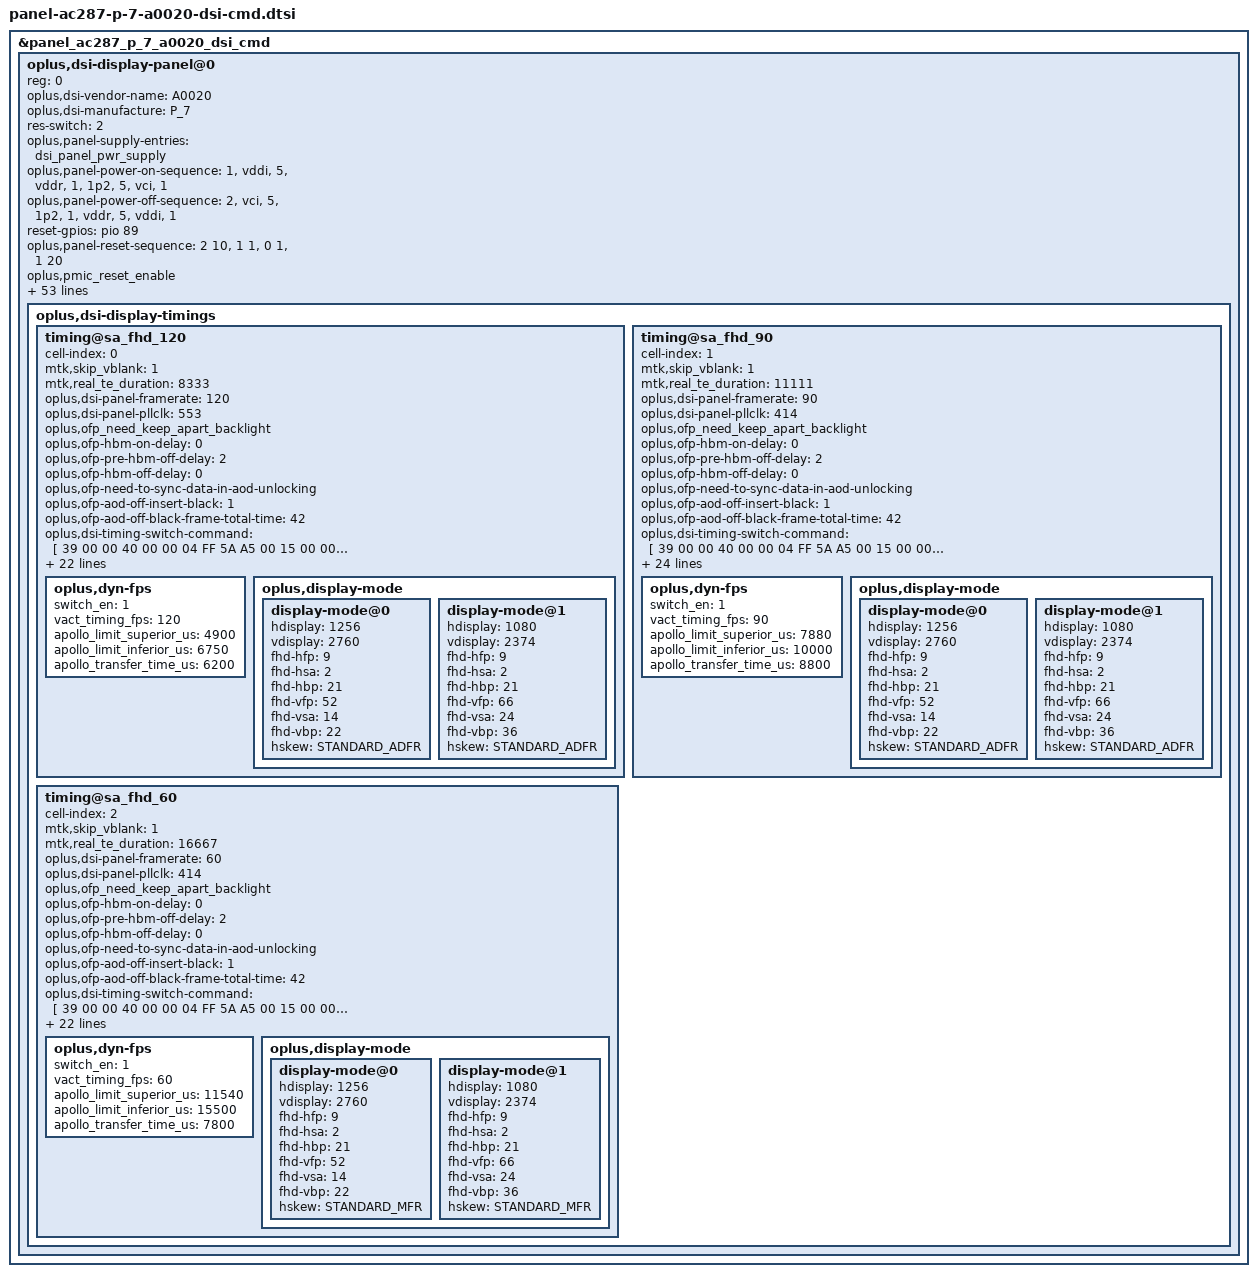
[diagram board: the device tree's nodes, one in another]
&panel_ac287_p_7_a0020_dsi_cmd {
	oplus,dsi-display-panel@0 {
		reg = <0>;
		oplus,dsi-vendor-name = "A0020";
		oplus,dsi-manufacture = "P_7";
		/* round corner */
		#include "panel-ac287-p-7-a0020-dsi-cmd-round-corner.dtsi"
		oplus,dsi-display-timings {
			timing@sa_fhd_120 {
				cell-index = <0>;
				mtk,skip_vblank = <1>;
				mtk,real_te_duration = <8333>;
				oplus,dsi-panel-framerate = <120>;
				oplus,dsi-panel-pllclk = <553>;
				/* OPLUS_FEATURE_DISPLAY_ONSCREENFINGERPRINT */
				oplus,ofp_need_keep_apart_backlight;
				oplus,ofp-hbm-on-delay = <0>;
				oplus,ofp-pre-hbm-off-delay = <2>;
				oplus,ofp-hbm-off-delay = <0>;
				oplus,ofp-need-to-sync-data-in-aod-unlocking;
				oplus,ofp-aod-off-insert-black = <1>;
				oplus,ofp-aod-off-black-frame-total-time = <42>;
				#include "panel-ac287-p-7-a0020-dsi-cmd-common.dtsi"
				oplus,dsi-timing-switch-command = [
					39 00 00 40 00 00 04 FF 5A A5 00
					15 00 00 40 00 00 02 60 00
					15 00 00 00 00 00 02 7D 00
				];
				oplus,dsi-on-command = [
					39 00 00 40 00 00 04 FF 5A A5 08 // 1~2: Sleepoutdon'treload
					15 00 00 40 00 00 02 C8 62
					39 00 00 40 00 00 04 FF 5A A5 21 // 3~4:  Flashreloadenable
					15 00 00 40 00 00 02 A4 38
					39 00 00 40 00 00 04 FF 5A A5 23
					15 00 00 40 00 00 02 85 15
					39 00 00 40 00 00 04 FF 5A A5 07
					15 00 00 40 00 00 02 8A 01
					39 00 00 40 00 00 03 8B 21 E0
					39 00 00 40 00 00 64 80 00 00 00 00 00 12 00 00 AB 30 80 0A C8 04 E8 00 14 02 74 02 74 02 00 02 56 00 20 01 B9 00 08 00 0D 05 7A 04 64 18 00 11 00 07 10 20 00 06 0F 0F 33 0E 1C 2A 38 46 54 62 69 70 77 79 7B 7D 7E 02 02 22 00 2A 40 2A BE 3A FC 3A FA 3A F8 3B 38 3B 78 3B B6 4B B6 4B F4 4B F4 6C 34 84 74 00 00 00 00 00 00
					39 00 00 40 00 00 64 81 00 00 00 00 00 12 00 00 A0 21 00 0A C8 04 E8 00 14 02 74 02 74 01 55 01 D6 00 0A 01 10 00 34 00 0D 05 7A 18 C0 08 00 0C 10 07 10 20 00 06 0F 0F 33 0E 1C 2A 38 46 54 62 69 70 77 79 7B 7D 7E 00 82 11 40 19 C0 22 3E 32 7C 3A BA 3A F8 3B 38 3B 38 3B 76 4B 76 4B 74 4B 74 5B B4 73 F4 01 00 00 00 00 00
					39 00 00 40 00 00 04 FF 5A A5 07
					15 00 00 40 00 00 02 91 00
					39 00 00 40 00 00 04 FF 5A A5 14
					15 00 00 40 00 00 02 82 01       //SPR IN AP ON
					39 00 00 40 00 00 04 FF 5A A5 14
					15 00 00 40 00 00 02 80 00      //DDIC SPR OFF
					// DDIC corner off
					39 00 00 40 00 00 04 FF 5A A5 17
					15 00 00 40 00 00 02 A0 0C
					39 00 00 40 00 00 04 FF 5A A5 13
					15 00 00 40 00 00 02 F9 30
					// 1 bit esd
					39 00 00 40 00 00 04 FF 5A A5 06
					15 00 00 40 00 00 02 C6 01
					39 00 00 40 00 00 04 FF 5A A5 08
					15 00 00 40 00 00 02 D2 05
					15 00 00 40 00 00 02 D3 01
					39 00 00 40 00 00 09 ED FF FF FF FF FF FF 45 FF
					39 00 00 40 00 00 09 EE FF FD FF FD F9 FA BE 76
					39 00 00 40 00 00 04 FF 5A A5 24
					39 00 00 40 00 00 31 D2 10 ED 04 83 03 0B 02 30 01 7A 00 FC 00 A9 00 01 00 00 00 00 00 00 00 00 00 00 00 00 00 00 00 00 00 00 00 00 00 00 00 00 00 00 00 00 00 00 00 00
					39 00 00 40 00 00 31 D3 04 84 03 0B 02 30 01 7A 00 FC 00 A9 00 01 00 00 00 00 00 00 00 00 00 00 00 00 00 00 00 00 00 00 00 00 00 00 00 00 00 00 00 00 00 00 00 00 00 00
					39 00 00 40 00 00 04 FF 5A A5 00
					15 00 00 40 00 00 02 5E 01
					15 00 00 40 00 00 02 60 00
					15 00 00 40 00 00 02 61 02
					15 00 00 40 00 00 02 6D 01
					15 00 00 40 00 00 02 35 00 //TE on
					15 00 00 40 00 00 02 53 20 // BC On
					// pull dowm pmic
					39 00 00 40 00 00 04 FF 5A A5 1C
					39 00 00 40 00 00 16 E1 10 80 9A 65 59 54 69 95 56 6A 55 99 9A 55 55 25 58 55 66 A2 00
					39 00 00 40 00 00 04 FF 5A A5 05
					15 00 00 40 00 00 02 83 01
					// LGOCB change to 30
					39 00 00 40 00 00 04 FF 5A A5 53
					39 00 00 40 00 00 1F A2 10 10 10 10 10 10 10 10 30 30 10 10 10 10 10 10 10 10 30 30 10 10 10 10 10 10 10 10 30 30
					39 00 00 00 00 00 04 FF 5A A5 00
					// crc reset
					39 00 00 40 00 00 04 FF 5A A5 08
					15 00 00 40 00 00 02 E0 22
					// timing switch
					39 00 00 40 00 00 04 FF 5A A5 22
					39 00 00 40 00 00 08 D8 00 FE 11 10 3A 18 18
					39 00 00 40 00 00 08 D9 01 03 11 10 50 18 18
					39 00 00 40 00 00 08 DA 01 04 11 10 50 19 19
					39 00 00 40 00 00 0A DC 84 94 BB 00 20 C4 A1 CC 10
					15 00 00 40 00 00 02 DD 01
					15 00 00 40 00 00 02 DE F1
					15 00 00 40 00 00 02 DF 80
					39 00 00 40 00 00 07 E0 02 00 5F 21 00 28
					39 00 00 40 00 00 04 FF 5A A5 00
					15 00 00 40 00 00 02 60 00
					15 00 00 00 00 00 02 7D 00
					// odc refresh
					39 00 00 40 00 00 04 FF 5A A5 49
					39 00 00 40 00 00 0C 80 00 08 0C 1C 3C 7C 8C CC 0C 00 01
					39 00 00 40 00 00 11 81 01 00 BD 00 18 01 85 01 42 02 A6 03 DD 06 FF 07
					39 00 00 40 00 00 13 82 01 00 BD 00 18 01 85 01 42 02 A6 03 DD 06 FF 07 00 00
					15 00 00 40 00 00 02 83 07
					15 00 00 40 00 00 02 84 0A
					39 00 00 40 00 00 04 85 08 0C 00
					39 00 00 40 00 00 04 86 40 80 00
					39 00 00 40 00 00 04 A0 40 40 40
					39 00 00 40 00 00 04 A1 40 40 40
					39 00 00 40 00 00 04 A2 40 40 40
					15 00 00 40 00 00 02 A6 3F
					15 00 00 40 00 00 02 A7 07
					15 00 00 40 00 00 02 AD 01
					15 00 00 40 00 00 02 AE 00
					15 00 00 40 00 00 02 AF 00
					15 00 00 40 00 00 02 D9 02
					15 00 00 40 00 00 02 DA F7
					15 00 00 40 00 00 02 DB 9C
					15 00 00 40 00 00 02 DC 03
					15 00 00 40 00 00 02 DF 06
					15 00 00 40 00 00 02 E0 01
					39 00 00 40 00 00 04 FF 5A A5 5A
					39 00 00 40 00 00 04 80 0D 0E 0D
					39 00 00 40 00 00 04 81 11 12 11
					39 00 00 40 00 00 04 82 07 08 07
					39 00 00 40 00 00 04 83 19 1C 1A
					39 00 00 40 00 00 04 84 14 15 13
					39 00 00 40 00 00 04 85 07 0A 08
					39 00 00 40 00 00 04 86 20 34 1A
					39 00 00 40 00 00 04 87 18 36 15
					39 00 00 40 00 00 04 88 1E 34 E0
					39 00 00 40 00 00 04 89 15 38 E0
					39 00 00 40 00 00 04 8A 32 32 32
					39 00 00 40 00 00 04 8B 2D 2D 28
					39 00 00 40 00 00 04 8C 27 1D 26
					39 00 00 40 00 00 04 8D 18 18 1D
					39 00 00 40 00 00 04 8E 0D 08 0D
					39 00 00 40 00 00 04 8F 20 24 24
					39 00 00 40 00 00 04 90 0D 10 10
					39 00 00 40 00 00 04 91 0F 10 10
					39 00 00 40 00 00 04 92 12 13 10
					39 00 00 40 00 00 04 93 05 05 06
					39 00 00 40 00 00 04 94 03 03 03
					39 00 00 40 00 00 04 95 33 37 3B
					39 00 00 40 00 00 04 96 32 33 2D
					39 00 00 40 00 00 04 97 26 27 22
					39 00 00 40 00 00 04 98 1A 1C 18
					39 00 00 40 00 00 04 99 12 13 10
					39 00 00 40 00 00 04 9A 06 07 06
					39 00 00 40 00 00 04 9B 04 04 03
					39 00 00 40 00 00 04 9C 36 3A 38
					39 00 00 40 00 00 04 9D 36 38 2D
					39 00 00 40 00 00 04 9E 24 26 16
					39 00 00 40 00 00 04 9F 1E 20 1C
					39 00 00 40 00 00 04 A0 15 17 14
					39 00 00 40 00 00 04 A1 0A 0B 0B
					39 00 00 40 00 00 04 A2 08 08 09
					39 00 00 40 00 00 04 A3 04 04 04
					39 00 00 40 00 00 04 A4 0B 0C 0B
					39 00 00 40 00 00 04 A5 0D 0E 0D
					39 00 00 40 00 00 04 A6 06 08 06
					39 00 00 40 00 00 04 A7 11 13 11
					39 00 00 40 00 00 04 A8 0F 10 10
					39 00 00 40 00 00 04 A9 05 06 05
					39 00 00 40 00 00 04 AA 19 1C 1B
					39 00 00 40 00 00 04 AB 14 17 15
					39 00 00 40 00 00 04 AC 0B 0F 0A
					39 00 00 40 00 00 04 AD 06 08 06
					39 00 00 40 00 00 04 AE 1B 1E 1B
					39 00 00 40 00 00 04 AF 18 1B 17
					39 00 00 40 00 00 04 B0 10 12 10
					39 00 00 40 00 00 04 B1 0D 0E 0A
					39 00 00 40 00 00 04 B2 03 05 04
					39 00 00 40 00 00 04 B3 18 1C 1A
					39 00 00 40 00 00 04 B4 16 18 16
					39 00 00 40 00 00 04 B5 12 14 10
					39 00 00 40 00 00 04 B6 07 0A 09
					39 00 00 40 00 00 04 B7 05 08 07
					39 00 00 40 00 00 04 B8 02 03 02
					39 00 00 40 00 00 04 B9 20 24 20
					39 00 00 40 00 00 04 BA 1C 1F 1D
					39 00 00 40 00 00 04 BB 16 1A 15
					39 00 00 40 00 00 04 BC 12 16 15
					39 00 00 40 00 00 04 BD 0B 0D 10
					39 00 00 40 00 00 04 BE 06 08 08
					39 00 00 40 00 00 04 BF 04 06 05
					39 00 00 40 00 00 04 C0 24 26 32
					39 00 00 40 00 00 04 C1 1D 17 23
					39 00 00 40 00 00 04 C2 1B 16 22
					39 00 00 40 00 00 04 C3 1A 17 20
					39 00 00 40 00 00 04 C4 17 16 1C
					39 00 00 40 00 00 04 C5 10 0F 0E
					39 00 00 40 00 00 04 C6 0F 0E 0B
					39 00 00 40 00 00 04 C7 0C 0D 0B
					39 00 00 40 00 00 04 C8 05 07 04
					39 00 00 40 00 00 04 C9 09 0C 09
					39 00 00 40 00 00 04 CA 04 06 05
					39 00 00 40 00 00 04 CB 14 1D 12
					39 00 00 40 00 00 04 CC 10 16 0D
					39 00 00 40 00 00 04 CD 03 05 02
					39 00 00 40 00 00 04 CE 0F 12 10
					39 00 00 40 00 00 04 CF 0E 10 0E
					39 00 00 40 00 00 04 D0 07 0A 08
					39 00 00 40 00 00 04 D1 02 04 01
					39 00 00 40 00 00 04 D2 17 1A 19
					39 00 00 40 00 00 04 D3 14 16 13
					39 00 00 40 00 00 04 D4 09 0C 0A
					39 00 00 40 00 00 04 D5 04 06 08
					39 00 00 40 00 00 04 D6 03 04 05
					39 00 00 40 00 00 04 D7 1D 1F 1C
					39 00 00 40 00 00 04 D8 0C 12 0D
					39 00 00 40 00 00 04 D9 09 0D 0B
					39 00 00 40 00 00 04 DA 06 0A 0A
					39 00 00 40 00 00 04 DB 05 05 07
					39 00 00 40 00 00 04 DC 01 03 01
					39 00 00 40 00 00 04 DD 22 23 20
					39 00 00 40 00 00 04 DE 15 18 1A
					39 00 00 40 00 00 04 DF 13 15 16
					39 00 00 40 00 00 04 E0 0F 13 14
					39 00 00 40 00 00 04 E1 0D 0F 10
					39 00 00 40 00 00 04 E2 07 08 08
					39 00 00 40 00 00 04 E3 06 07 06
					39 00 00 40 00 00 04 E4 2F 2D 35
					39 00 00 40 00 00 04 E5 20 20 28
					39 00 00 40 00 00 04 E6 1E 24 29
					39 00 00 40 00 00 04 E7 1B 1A 23
					39 00 00 40 00 00 04 E8 1B 1F 1E
					39 00 00 40 00 00 04 E9 0E 13 11
					39 00 00 40 00 00 04 EA 0B 10 0F
					39 00 00 40 00 00 04 EB 09 0A 07
					39 00 00 40 00 00 04 FF 5A A5 5B
					39 00 00 40 00 00 04 80 05 07 04
					39 00 00 40 00 00 04 81 05 08 07
					39 00 00 40 00 00 04 82 04 04 05
					39 00 00 40 00 00 04 83 11 16 0F
					39 00 00 40 00 00 04 84 0F 11 0D
					39 00 00 40 00 00 04 85 03 05 02
					39 00 00 40 00 00 04 86 08 0B 07
					39 00 00 40 00 00 04 87 04 05 06
					39 00 00 40 00 00 04 88 03 04 03
					39 00 00 40 00 00 04 89 02 02 01
					39 00 00 40 00 00 04 8A 11 14 13
					39 00 00 40 00 00 04 8B 0B 0D 0E
					39 00 00 40 00 00 04 8C 06 07 09
					39 00 00 40 00 00 04 8D 05 06 08
					39 00 00 40 00 00 04 8E 04 04 05
					39 00 00 40 00 00 04 8F 1A 1F 1D
					39 00 00 40 00 00 04 90 14 16 15
					39 00 00 40 00 00 04 91 0E 11 0F
					39 00 00 40 00 00 04 92 07 0A 09
					39 00 00 40 00 00 04 93 06 05 07
					39 00 00 40 00 00 04 94 02 03 01
					39 00 00 40 00 00 04 95 2E 32 31
					39 00 00 40 00 00 04 96 28 2C 2A
					39 00 00 40 00 00 04 97 18 1D 19
					39 00 00 40 00 00 04 98 13 14 13
					39 00 00 40 00 00 04 99 0F 0E 0F
					39 00 00 40 00 00 04 9A 07 08 08
					39 00 00 40 00 00 04 9B 06 07 06
					39 00 00 40 00 00 04 9C 2D 2E 3F
					39 00 00 40 00 00 04 9D 21 20 29
					39 00 00 40 00 00 04 9E 21 20 29
					39 00 00 40 00 00 04 9F 21 20 25
					39 00 00 40 00 00 04 A0 1B 17 1C
					39 00 00 40 00 00 04 A1 10 0F 13
					39 00 00 40 00 00 04 A2 0E 0D 0F
					39 00 00 40 00 00 04 A3 08 08 05
					39 00 00 40 00 00 04 A4 05 08 04
					39 00 00 40 00 00 04 A5 05 07 04
					39 00 00 40 00 00 04 A6 04 05 04
					39 00 00 40 00 00 04 A7 05 07 05
					39 00 00 40 00 00 04 A8 04 06 03
					39 00 00 40 00 00 04 A9 02 03 02
					39 00 00 40 00 00 04 AA 0F 11 10
					39 00 00 40 00 00 04 AB 0A 0B 08
					39 00 00 40 00 00 04 AC 06 07 05
					39 00 00 40 00 00 04 AD 03 02 02
					39 00 00 40 00 00 04 AE 11 14 12
					39 00 00 40 00 00 04 AF 0C 0F 0E
					39 00 00 40 00 00 04 B0 0B 0A 0A
					39 00 00 40 00 00 04 B1 05 07 08
					39 00 00 40 00 00 04 B2 04 04 05
					39 00 00 40 00 00 04 B3 16 15 14
					39 00 00 40 00 00 04 B4 0F 10 10
					39 00 00 40 00 00 04 B5 0D 0C 0B
					39 00 00 40 00 00 04 B6 09 08 07
					39 00 00 40 00 00 04 B7 05 05 06
					39 00 00 40 00 00 04 B8 01 01 01
					39 00 00 40 00 00 04 B9 1D 1C 21
					39 00 00 40 00 00 04 BA 16 16 1C
					39 00 00 40 00 00 04 BB 14 14 19
					39 00 00 40 00 00 04 BC 12 13 15
					39 00 00 40 00 00 04 BD 0D 0D 10
					39 00 00 40 00 00 04 BE 06 07 08
					39 00 00 40 00 00 04 BF 05 06 06
					39 00 00 40 00 00 04 C0 27 2E 3E
					39 00 00 40 00 00 04 C1 22 1C 2D
					39 00 00 40 00 00 04 C2 1E 20 26
					39 00 00 40 00 00 04 C3 1E 24 25
					39 00 00 40 00 00 04 C4 17 14 1A
					39 00 00 40 00 00 04 C5 0E 0F 0E
					39 00 00 40 00 00 04 C6 0C 0C 0D
					39 00 00 40 00 00 04 C7 04 05 05
					39 00 00 40 00 00 04 C8 05 07 04
					39 00 00 40 00 00 04 C9 04 06 04
					39 00 00 40 00 00 04 CA 03 04 03
					39 00 00 40 00 00 04 CB 07 07 08
					39 00 00 40 00 00 04 CC 02 03 03
					39 00 00 40 00 00 04 CD 00 01 01
					39 00 00 40 00 00 04 CE 06 06 08
					39 00 00 40 00 00 04 CF 03 04 03
					39 00 00 40 00 00 04 D0 02 03 02
					39 00 00 40 00 00 04 D1 01 03 01
					39 00 00 40 00 00 04 D2 11 11 14
					39 00 00 40 00 00 04 D3 0B 0C 0C
					39 00 00 40 00 00 04 D4 09 0A 0B
					39 00 00 40 00 00 04 D5 07 08 09
					39 00 00 40 00 00 04 D6 05 04 05
					39 00 00 40 00 00 04 D7 15 16 18
					39 00 00 40 00 00 04 D8 10 12 16
					39 00 00 40 00 00 04 D9 0D 0C 0F
					39 00 00 40 00 00 04 DA 09 0B 0B
					39 00 00 40 00 00 04 DB 07 06 07
					39 00 00 40 00 00 04 DC 01 01 01
					39 00 00 40 00 00 04 DD 23 1F 2C
					39 00 00 40 00 00 04 DE 1A 1C 1F
					39 00 00 40 00 00 04 DF 18 19 1B
					39 00 00 40 00 00 04 E0 13 16 16
					39 00 00 40 00 00 04 E1 0F 0F 10
					39 00 00 40 00 00 04 E2 07 08 07
					39 00 00 40 00 00 04 E3 05 06 06
					39 00 00 40 00 00 04 E4 37 36 3A
					39 00 00 40 00 00 04 E5 28 28 2D
					39 00 00 40 00 00 04 E6 27 27 2B
					39 00 00 40 00 00 04 E7 1D 22 23
					39 00 00 40 00 00 04 E8 1A 1A 19
					39 00 00 40 00 00 04 E9 10 0E 10
					39 00 00 40 00 00 04 EA 0E 0C 0D
					39 00 00 40 00 00 04 EB 05 05 05
					39 00 00 40 00 00 04 FF 5A A5 5C
					39 00 00 40 00 00 04 80 03 05 04
					39 00 00 40 00 00 04 81 03 03 03
					39 00 00 40 00 00 04 82 02 02 02
					39 00 00 40 00 00 04 83 04 05 04
					39 00 00 40 00 00 04 84 02 03 03
					39 00 00 40 00 00 04 85 01 02 02
					39 00 00 40 00 00 04 86 12 14 13
					39 00 00 40 00 00 04 87 0D 0E 0C
					39 00 00 40 00 00 04 88 0A 08 07
					39 00 00 40 00 00 04 89 04 04 03
					39 00 00 40 00 00 04 8A 1C 1C 1B
					39 00 00 40 00 00 04 8B 16 16 14
					39 00 00 40 00 00 04 8C 10 0F 0F
					39 00 00 40 00 00 04 8D 0A 0C 0A
					39 00 00 40 00 00 04 8E 05 07 06
					39 00 00 40 00 00 04 8F 20 21 22
					39 00 00 40 00 00 04 90 1C 1E 1D
					39 00 00 40 00 00 04 91 13 14 14
					39 00 00 40 00 00 04 92 0E 0F 0D
					39 00 00 40 00 00 04 93 05 07 06
					39 00 00 40 00 00 04 94 01 03 01
					39 00 00 40 00 00 04 95 2E 2E 33
					39 00 00 40 00 00 04 96 1D 1F 26
					39 00 00 40 00 00 04 97 17 1A 1C
					39 00 00 40 00 00 04 98 12 15 16
					39 00 00 40 00 00 04 99 0F 11 13
					39 00 00 40 00 00 04 9A 06 08 07
					39 00 00 40 00 00 04 9B 05 06 05
					39 00 00 40 00 00 04 9C 34 36 33
					39 00 00 40 00 00 04 9D 29 2C 29
					39 00 00 40 00 00 04 9E 29 2B 24
					39 00 00 40 00 00 04 9F 22 21 22
					39 00 00 40 00 00 04 A0 19 1F 18
					39 00 00 40 00 00 04 A1 0D 11 0C
					39 00 00 40 00 00 04 A2 0A 0D 0C
					39 00 00 40 00 00 04 A3 00 00 00
					39 00 00 40 00 00 04 A4 02 02 02
					39 00 00 40 00 00 04 A5 01 01 02
					39 00 00 40 00 00 04 A6 01 02 01
					39 00 00 40 00 00 04 A7 07 08 09
					39 00 00 40 00 00 04 A8 03 03 04
					39 00 00 40 00 00 04 A9 02 02 03
					39 00 00 40 00 00 04 AA 10 10 11
					39 00 00 40 00 00 04 AB 0E 0F 10
					39 00 00 40 00 00 04 AC 0A 0B 0C
					39 00 00 40 00 00 04 AD 04 04 04
					39 00 00 40 00 00 04 AE 18 19 1A
					39 00 00 40 00 00 04 AF 16 15 15
					39 00 00 40 00 00 04 B0 12 11 10
					39 00 00 40 00 00 04 B1 0C 0D 0D
					39 00 00 40 00 00 04 B2 05 05 05
					39 00 00 40 00 00 04 B3 21 20 22
					39 00 00 40 00 00 04 B4 18 17 16
					39 00 00 40 00 00 04 B5 0F 10 10
					39 00 00 40 00 00 04 B6 0C 0B 0D
					39 00 00 40 00 00 04 B7 07 06 07
					39 00 00 40 00 00 04 B8 01 01 01
					39 00 00 40 00 00 04 B9 32 30 36
					39 00 00 40 00 00 04 BA 1A 1B 1B
					39 00 00 40 00 00 04 BB 18 1A 18
					39 00 00 40 00 00 04 BC 13 14 13
					39 00 00 40 00 00 04 BD 0E 10 0C
					39 00 00 40 00 00 04 BE 06 08 05
					39 00 00 40 00 00 04 BF 05 05 04
					39 00 00 40 00 00 04 C0 30 2C 32
					39 00 00 40 00 00 04 C1 25 2A 26
					39 00 00 40 00 00 04 C2 1D 2C 22
					39 00 00 40 00 00 04 C3 1A 1E 1C
					39 00 00 40 00 00 04 C4 16 1C 12
					39 00 00 40 00 00 04 C5 0C 10 0A
					39 00 00 40 00 00 04 C6 0B 0C 08
					39 00 00 40 00 00 04 C7 00 00 00
					39 00 00 40 00 00 04 C8 05 06 03
					39 00 00 40 00 00 04 C9 03 05 02
					39 00 00 40 00 00 04 CA 03 05 02
					39 00 00 40 00 00 04 CB 03 05 02
					39 00 00 40 00 00 04 CC 02 03 02
					39 00 00 40 00 00 04 CD 00 00 00
					39 00 00 40 00 00 04 CE 00 00 00
					39 00 00 40 00 00 04 CF 00 00 00
					39 00 00 00 00 00 04 FF 5A A5 00
					39 00 00 00 78 00 01 11 // Sleep out
					39 00 00 00 00 00 01 29 // Display out
				];
				oplus,dsi-aod-off-command = [
					39 00 00 40 00 00 04 FF 5A A5 00
					39 00 00 40 00 00 02 38 00
					39 00 00 00 00 00 05 51 00 00 00 00
				];
				oplus,dsi-ultra-low-power-aod-on-command = [
				];
				oplus,dsi-ultra-low-power-aod-off-command = [
				];
				oplus,dsi-hbm-on-command = [
					39 00 00 00 00 00 03 51 0E 7A
				];
				oplus,dsi-hbm-off-command = [
					39 00 00 00 00 00 03 51 0D BB
				];

				oplus,dsi-timing-switch-command-state = "dsi_hs_mode";
				oplus,dsi-on-command-state = "dsi_lp_mode";
				oplus,dsi-aod-off-command-state = "dsi_ls_mode";
				oplus,dsi-ultra-low-power-aod-on-command-state = "dsi_ls_mode";
				oplus,dsi-ultra-low-power-aod-off-command-state = "dsi_ls_mode";
				oplus,dsi-hbm-on-command-state = "dsi_hs_mode";
				oplus,dsi-hbm-off-command-state = "dsi_hs_mode";
				oplus,dsc-params-entries = <&dsc_params>;
				oplus,spr-params-entries = <&spr_params>;
				oplus,dyn-fps {
					switch_en = <1>;
					vact_timing_fps = <120>;
					apollo_limit_superior_us = <4900>;
					apollo_limit_inferior_us = <6750>;
					apollo_transfer_time_us = <6200>;
				};
				oplus,display-mode {
					display-mode@0 {
						hdisplay = <1256>;
						vdisplay = <2760>;
						fhd-hfp = <9>;
						fhd-hsa = <2>;
						fhd-hbp = <21>;
						fhd-vfp = <52>;
						fhd-vsa = <14>;
						fhd-vbp = <22>;
						hskew = <STANDARD_ADFR>;
					};
					display-mode@1 {
						hdisplay = <1080>;
						vdisplay = <2374>;
						fhd-hfp = <9>;
						fhd-hsa = <2>;
						fhd-hbp = <21>;
						fhd-vfp = <66>;
						fhd-vsa = <24>;
						fhd-vbp = <36>;
						hskew = <STANDARD_ADFR>;
					};
				};
			};
			timing@sa_fhd_90 {
				cell-index = <1>;
				mtk,skip_vblank = <1>;
				mtk,real_te_duration = <11111>;
				oplus,dsi-panel-framerate = <90>;
				oplus,dsi-panel-pllclk = <414>;
				/* OPLUS_FEATURE_DISPLAY_ONSCREENFINGERPRINT */
				oplus,ofp_need_keep_apart_backlight;
				oplus,ofp-hbm-on-delay = <0>;
				oplus,ofp-pre-hbm-off-delay = <2>;
				oplus,ofp-hbm-off-delay = <0>;
				oplus,ofp-need-to-sync-data-in-aod-unlocking;
				oplus,ofp-aod-off-insert-black = <1>;
				oplus,ofp-aod-off-black-frame-total-time = <42>;
				#include "panel-ac287-p-7-a0020-dsi-cmd-common.dtsi"
				oplus,dsi-timing-switch-command = [
					39 00 00 40 00 00 04 FF 5A A5 00
					15 00 00 40 00 00 02 60 03
					15 00 00 00 00 00 02 7D 01
				];
				oplus,dsi-on-command = [
					39 00 00 40 00 00 04 FF 5A A5 08 // 1~2: Sleepoutdon'treload
					15 00 00 40 00 00 02 C8 62
					39 00 00 40 00 00 04 FF 5A A5 21 // 3~4:  Flashreloadenable
					15 00 00 40 00 00 02 A4 38
					39 00 00 40 00 00 04 FF 5A A5 23
					15 00 00 40 00 00 02 85 15
					39 00 00 40 00 00 04 FF 5A A5 07
					15 00 00 40 00 00 02 8A 01
					39 00 00 40 00 00 03 8B 21 E0
					39 00 00 40 00 00 64 80 00 00 00 00 00 12 00 00 AB 30 80 0A C8 04 E8 00 14 02 74 02 74 02 00 02 56 00 20 01 B9 00 08 00 0D 05 7A 04 64 18 00 11 00 07 10 20 00 06 0F 0F 33 0E 1C 2A 38 46 54 62 69 70 77 79 7B 7D 7E 02 02 22 00 2A 40 2A BE 3A FC 3A FA 3A F8 3B 38 3B 78 3B B6 4B B6 4B F4 4B F4 6C 34 84 74 00 00 00 00 00 00
					39 00 00 40 00 00 64 81 00 00 00 00 00 12 00 00 A0 21 00 0A C8 04 E8 00 14 02 74 02 74 01 55 01 D6 00 0A 01 10 00 34 00 0D 05 7A 18 C0 08 00 0C 10 07 10 20 00 06 0F 0F 33 0E 1C 2A 38 46 54 62 69 70 77 79 7B 7D 7E 00 82 11 40 19 C0 22 3E 32 7C 3A BA 3A F8 3B 38 3B 38 3B 76 4B 76 4B 74 4B 74 5B B4 73 F4 01 00 00 00 00 00
					39 00 00 40 00 00 04 FF 5A A5 07
					15 00 00 40 00 00 02 91 00
					39 00 00 40 00 00 04 FF 5A A5 14
					15 00 00 40 00 00 02 82 01       //SPR IN AP ON
					39 00 00 40 00 00 04 FF 5A A5 14
					15 00 00 40 00 00 02 80 00      //DDIC SPR OFF
					// DDIC corner off
					39 00 00 40 00 00 04 FF 5A A5 17
					15 00 00 40 00 00 02 A0 0C
					39 00 00 40 00 00 04 FF 5A A5 13
					15 00 00 40 00 00 02 F9 30
					// 1 bit esd
					39 00 00 40 00 00 04 FF 5A A5 06
					15 00 00 40 00 00 02 C6 01
					39 00 00 40 00 00 04 FF 5A A5 08
					15 00 00 40 00 00 02 D2 05
					15 00 00 40 00 00 02 D3 01
					39 00 00 40 00 00 09 ED FF FF FF FF FF FF 45 FF
					39 00 00 40 00 00 09 EE FF FD FF FD F9 FA BE 76
					39 00 00 40 00 00 04 FF 5A A5 24
					39 00 00 40 00 00 31 D2 10 ED 04 83 03 0B 02 30 01 7A 00 FC 00 A9 00 01 00 00 00 00 00 00 00 00 00 00 00 00 00 00 00 00 00 00 00 00 00 00 00 00 00 00 00 00 00 00 00 00
					39 00 00 40 00 00 31 D3 04 84 03 0B 02 30 01 7A 00 FC 00 A9 00 01 00 00 00 00 00 00 00 00 00 00 00 00 00 00 00 00 00 00 00 00 00 00 00 00 00 00 00 00 00 00 00 00 00 00
					39 00 00 40 00 00 04 FF 5A A5 00
					15 00 00 40 00 00 02 5E 01
					15 00 00 40 00 00 02 60 00
					15 00 00 40 00 00 02 61 02
					15 00 00 40 00 00 02 6D 01
					15 00 00 40 00 00 02 35 00 //TE on
					15 00 00 40 00 00 02 53 20 // BC On
					// pull dowm pmic
					39 00 00 40 00 00 04 FF 5A A5 1C
					39 00 00 40 00 00 16 E1 10 80 9A 65 59 54 69 95 56 6A 55 99 9A 55 55 25 58 55 66 A2 00
					39 00 00 40 00 00 04 FF 5A A5 05
					15 00 00 40 00 00 02 83 01
					// LGOCB change to 30
					39 00 00 40 00 00 04 FF 5A A5 53
					39 00 00 40 00 00 1F A2 10 10 10 10 10 10 10 10 30 30 10 10 10 10 10 10 10 10 30 30 10 10 10 10 10 10 10 10 30 30
					39 00 00 00 00 00 04 FF 5A A5 00
					// crc reset
					39 00 00 40 00 00 04 FF 5A A5 08
					15 00 00 40 00 00 02 E0 22
					// timing switch
					39 00 00 40 00 00 04 FF 5A A5 22
					39 00 00 40 00 00 08 D8 00 FE 11 10 3A 18 18
					39 00 00 40 00 00 08 D9 01 03 11 10 50 18 18
					39 00 00 40 00 00 08 DA 01 04 11 10 50 19 19
					39 00 00 40 00 00 0A DC 84 94 BB 00 20 C4 A1 CC 10
					15 00 00 40 00 00 02 DD 01
					15 00 00 40 00 00 02 DE F1
					15 00 00 40 00 00 02 DF 80
					39 00 00 40 00 00 07 E0 02 00 5F 21 00 28
					39 00 00 40 00 00 04 FF 5A A5 00
					15 00 00 40 00 00 02 60 03
					15 00 00 00 00 00 02 7D 01
					// odc refresh
					39 00 00 40 00 00 04 FF 5A A5 49
					39 00 00 40 00 00 0C 80 00 08 0C 1C 3C 7C 8C CC 0C 00 01
					39 00 00 40 00 00 11 81 01 00 BD 00 18 01 85 01 42 02 A6 03 DD 06 FF 07
					39 00 00 40 00 00 13 82 01 00 BD 00 18 01 85 01 42 02 A6 03 DD 06 FF 07 00 00
					15 00 00 40 00 00 02 83 07
					15 00 00 40 00 00 02 84 0A
					39 00 00 40 00 00 04 85 08 0C 00
					39 00 00 40 00 00 04 86 40 80 00
					39 00 00 40 00 00 04 A0 40 40 40
					39 00 00 40 00 00 04 A1 40 40 40
					39 00 00 40 00 00 04 A2 40 40 40
					15 00 00 40 00 00 02 A6 3F
					15 00 00 40 00 00 02 A7 07
					15 00 00 40 00 00 02 AD 01
					15 00 00 40 00 00 02 AE 00
					15 00 00 40 00 00 02 AF 00
					15 00 00 40 00 00 02 D9 02
					15 00 00 40 00 00 02 DA F7
					15 00 00 40 00 00 02 DB 9C
					15 00 00 40 00 00 02 DC 03
					15 00 00 40 00 00 02 DF 06
					15 00 00 40 00 00 02 E0 01
					39 00 00 40 00 00 04 FF 5A A5 5A
					39 00 00 40 00 00 04 80 0D 0E 0D
					39 00 00 40 00 00 04 81 11 12 11
					39 00 00 40 00 00 04 82 07 08 07
					39 00 00 40 00 00 04 83 19 1C 1A
					39 00 00 40 00 00 04 84 14 15 13
					39 00 00 40 00 00 04 85 07 0A 08
					39 00 00 40 00 00 04 86 20 34 1A
					39 00 00 40 00 00 04 87 18 36 15
					39 00 00 40 00 00 04 88 1E 34 E0
					39 00 00 40 00 00 04 89 15 38 E0
					39 00 00 40 00 00 04 8A 32 32 32
					39 00 00 40 00 00 04 8B 2D 2D 28
					39 00 00 40 00 00 04 8C 27 1D 26
					39 00 00 40 00 00 04 8D 18 18 1D
					39 00 00 40 00 00 04 8E 0D 08 0D
					39 00 00 40 00 00 04 8F 20 24 24
					39 00 00 40 00 00 04 90 0D 10 10
					39 00 00 40 00 00 04 91 0F 10 10
					39 00 00 40 00 00 04 92 12 13 10
					39 00 00 40 00 00 04 93 05 05 06
					39 00 00 40 00 00 04 94 03 03 03
					39 00 00 40 00 00 04 95 33 37 3B
					39 00 00 40 00 00 04 96 32 33 2D
					39 00 00 40 00 00 04 97 26 27 22
					39 00 00 40 00 00 04 98 1A 1C 18
					39 00 00 40 00 00 04 99 12 13 10
					39 00 00 40 00 00 04 9A 06 07 06
					39 00 00 40 00 00 04 9B 04 04 03
					39 00 00 40 00 00 04 9C 36 3A 38
					39 00 00 40 00 00 04 9D 36 38 2D
					39 00 00 40 00 00 04 9E 24 26 16
					39 00 00 40 00 00 04 9F 1E 20 1C
					39 00 00 40 00 00 04 A0 15 17 14
					39 00 00 40 00 00 04 A1 0A 0B 0B
					39 00 00 40 00 00 04 A2 08 08 09
					39 00 00 40 00 00 04 A3 04 04 04
					39 00 00 40 00 00 04 A4 0B 0C 0B
					39 00 00 40 00 00 04 A5 0D 0E 0D
					39 00 00 40 00 00 04 A6 06 08 06
					39 00 00 40 00 00 04 A7 11 13 11
					39 00 00 40 00 00 04 A8 0F 10 10
					39 00 00 40 00 00 04 A9 05 06 05
					39 00 00 40 00 00 04 AA 19 1C 1B
					39 00 00 40 00 00 04 AB 14 17 15
					39 00 00 40 00 00 04 AC 0B 0F 0A
					39 00 00 40 00 00 04 AD 06 08 06
					39 00 00 40 00 00 04 AE 1B 1E 1B
					39 00 00 40 00 00 04 AF 18 1B 17
					39 00 00 40 00 00 04 B0 10 12 10
					39 00 00 40 00 00 04 B1 0D 0E 0A
					39 00 00 40 00 00 04 B2 03 05 04
					39 00 00 40 00 00 04 B3 18 1C 1A
					39 00 00 40 00 00 04 B4 16 18 16
					39 00 00 40 00 00 04 B5 12 14 10
					39 00 00 40 00 00 04 B6 07 0A 09
					39 00 00 40 00 00 04 B7 05 08 07
					39 00 00 40 00 00 04 B8 02 03 02
					39 00 00 40 00 00 04 B9 20 24 20
					39 00 00 40 00 00 04 BA 1C 1F 1D
					39 00 00 40 00 00 04 BB 16 1A 15
					39 00 00 40 00 00 04 BC 12 16 15
					39 00 00 40 00 00 04 BD 0B 0D 10
					39 00 00 40 00 00 04 BE 06 08 08
					39 00 00 40 00 00 04 BF 04 06 05
					39 00 00 40 00 00 04 C0 24 26 32
					39 00 00 40 00 00 04 C1 1D 17 23
					39 00 00 40 00 00 04 C2 1B 16 22
					39 00 00 40 00 00 04 C3 1A 17 20
					39 00 00 40 00 00 04 C4 17 16 1C
					39 00 00 40 00 00 04 C5 10 0F 0E
					39 00 00 40 00 00 04 C6 0F 0E 0B
					39 00 00 40 00 00 04 C7 0C 0D 0B
					39 00 00 40 00 00 04 C8 05 07 04
					39 00 00 40 00 00 04 C9 09 0C 09
					39 00 00 40 00 00 04 CA 04 06 05
					39 00 00 40 00 00 04 CB 14 1D 12
					39 00 00 40 00 00 04 CC 10 16 0D
					39 00 00 40 00 00 04 CD 03 05 02
					39 00 00 40 00 00 04 CE 0F 12 10
					39 00 00 40 00 00 04 CF 0E 10 0E
					39 00 00 40 00 00 04 D0 07 0A 08
					39 00 00 40 00 00 04 D1 02 04 01
					39 00 00 40 00 00 04 D2 17 1A 19
					39 00 00 40 00 00 04 D3 14 16 13
					39 00 00 40 00 00 04 D4 09 0C 0A
					39 00 00 40 00 00 04 D5 04 06 08
					39 00 00 40 00 00 04 D6 03 04 05
					39 00 00 40 00 00 04 D7 1D 1F 1C
					39 00 00 40 00 00 04 D8 0C 12 0D
					39 00 00 40 00 00 04 D9 09 0D 0B
					39 00 00 40 00 00 04 DA 06 0A 0A
					39 00 00 40 00 00 04 DB 05 05 07
					39 00 00 40 00 00 04 DC 01 03 01
					39 00 00 40 00 00 04 DD 22 23 20
					39 00 00 40 00 00 04 DE 15 18 1A
					39 00 00 40 00 00 04 DF 13 15 16
					39 00 00 40 00 00 04 E0 0F 13 14
					39 00 00 40 00 00 04 E1 0D 0F 10
					39 00 00 40 00 00 04 E2 07 08 08
					39 00 00 40 00 00 04 E3 06 07 06
					39 00 00 40 00 00 04 E4 2F 2D 35
					39 00 00 40 00 00 04 E5 20 20 28
					39 00 00 40 00 00 04 E6 1E 24 29
					39 00 00 40 00 00 04 E7 1B 1A 23
					39 00 00 40 00 00 04 E8 1B 1F 1E
					39 00 00 40 00 00 04 E9 0E 13 11
					39 00 00 40 00 00 04 EA 0B 10 0F
					39 00 00 40 00 00 04 EB 09 0A 07
					39 00 00 40 00 00 04 FF 5A A5 5B
					39 00 00 40 00 00 04 80 05 07 04
					39 00 00 40 00 00 04 81 05 08 07
					39 00 00 40 00 00 04 82 04 04 05
					39 00 00 40 00 00 04 83 11 16 0F
					39 00 00 40 00 00 04 84 0F 11 0D
					39 00 00 40 00 00 04 85 03 05 02
					39 00 00 40 00 00 04 86 08 0B 07
					39 00 00 40 00 00 04 87 04 05 06
					39 00 00 40 00 00 04 88 03 04 03
					39 00 00 40 00 00 04 89 02 02 01
					39 00 00 40 00 00 04 8A 11 14 13
					39 00 00 40 00 00 04 8B 0B 0D 0E
					39 00 00 40 00 00 04 8C 06 07 09
					39 00 00 40 00 00 04 8D 05 06 08
					39 00 00 40 00 00 04 8E 04 04 05
					39 00 00 40 00 00 04 8F 1A 1F 1D
					39 00 00 40 00 00 04 90 14 16 15
					39 00 00 40 00 00 04 91 0E 11 0F
					39 00 00 40 00 00 04 92 07 0A 09
					39 00 00 40 00 00 04 93 06 05 07
					39 00 00 40 00 00 04 94 02 03 01
					39 00 00 40 00 00 04 95 2E 32 31
					39 00 00 40 00 00 04 96 28 2C 2A
					39 00 00 40 00 00 04 97 18 1D 19
					39 00 00 40 00 00 04 98 13 14 13
					39 00 00 40 00 00 04 99 0F 0E 0F
					39 00 00 40 00 00 04 9A 07 08 08
					39 00 00 40 00 00 04 9B 06 07 06
					39 00 00 40 00 00 04 9C 2D 2E 3F
					39 00 00 40 00 00 04 9D 21 20 29
					39 00 00 40 00 00 04 9E 21 20 29
					39 00 00 40 00 00 04 9F 21 20 25
					39 00 00 40 00 00 04 A0 1B 17 1C
					39 00 00 40 00 00 04 A1 10 0F 13
					39 00 00 40 00 00 04 A2 0E 0D 0F
					39 00 00 40 00 00 04 A3 08 08 05
					39 00 00 40 00 00 04 A4 05 08 04
					39 00 00 40 00 00 04 A5 05 07 04
					39 00 00 40 00 00 04 A6 04 05 04
					39 00 00 40 00 00 04 A7 05 07 05
					39 00 00 40 00 00 04 A8 04 06 03
					39 00 00 40 00 00 04 A9 02 03 02
					39 00 00 40 00 00 04 AA 0F 11 10
					39 00 00 40 00 00 04 AB 0A 0B 08
					39 00 00 40 00 00 04 AC 06 07 05
					39 00 00 40 00 00 04 AD 03 02 02
					39 00 00 40 00 00 04 AE 11 14 12
					39 00 00 40 00 00 04 AF 0C 0F 0E
					39 00 00 40 00 00 04 B0 0B 0A 0A
					39 00 00 40 00 00 04 B1 05 07 08
					39 00 00 40 00 00 04 B2 04 04 05
					39 00 00 40 00 00 04 B3 16 15 14
					39 00 00 40 00 00 04 B4 0F 10 10
					39 00 00 40 00 00 04 B5 0D 0C 0B
					39 00 00 40 00 00 04 B6 09 08 07
					39 00 00 40 00 00 04 B7 05 05 06
					39 00 00 40 00 00 04 B8 01 01 01
					39 00 00 40 00 00 04 B9 1D 1C 21
					39 00 00 40 00 00 04 BA 16 16 1C
					39 00 00 40 00 00 04 BB 14 14 19
					39 00 00 40 00 00 04 BC 12 13 15
					39 00 00 40 00 00 04 BD 0D 0D 10
					39 00 00 40 00 00 04 BE 06 07 08
					39 00 00 40 00 00 04 BF 05 06 06
					39 00 00 40 00 00 04 C0 27 2E 3E
					39 00 00 40 00 00 04 C1 22 1C 2D
					39 00 00 40 00 00 04 C2 1E 20 26
					39 00 00 40 00 00 04 C3 1E 24 25
					39 00 00 40 00 00 04 C4 17 14 1A
					39 00 00 40 00 00 04 C5 0E 0F 0E
					39 00 00 40 00 00 04 C6 0C 0C 0D
					39 00 00 40 00 00 04 C7 04 05 05
					39 00 00 40 00 00 04 C8 05 07 04
					39 00 00 40 00 00 04 C9 04 06 04
					39 00 00 40 00 00 04 CA 03 04 03
					39 00 00 40 00 00 04 CB 07 07 08
					39 00 00 40 00 00 04 CC 02 03 03
					39 00 00 40 00 00 04 CD 00 01 01
					39 00 00 40 00 00 04 CE 06 06 08
					39 00 00 40 00 00 04 CF 03 04 03
					39 00 00 40 00 00 04 D0 02 03 02
					39 00 00 40 00 00 04 D1 01 03 01
					39 00 00 40 00 00 04 D2 11 11 14
					39 00 00 40 00 00 04 D3 0B 0C 0C
					39 00 00 40 00 00 04 D4 09 0A 0B
					39 00 00 40 00 00 04 D5 07 08 09
					39 00 00 40 00 00 04 D6 05 04 05
					39 00 00 40 00 00 04 D7 15 16 18
					39 00 00 40 00 00 04 D8 10 12 16
					39 00 00 40 00 00 04 D9 0D 0C 0F
					39 00 00 40 00 00 04 DA 09 0B 0B
					39 00 00 40 00 00 04 DB 07 06 07
					39 00 00 40 00 00 04 DC 01 01 01
					39 00 00 40 00 00 04 DD 23 1F 2C
					39 00 00 40 00 00 04 DE 1A 1C 1F
					39 00 00 40 00 00 04 DF 18 19 1B
					39 00 00 40 00 00 04 E0 13 16 16
					39 00 00 40 00 00 04 E1 0F 0F 10
					39 00 00 40 00 00 04 E2 07 08 07
					39 00 00 40 00 00 04 E3 05 06 06
					39 00 00 40 00 00 04 E4 37 36 3A
					39 00 00 40 00 00 04 E5 28 28 2D
					39 00 00 40 00 00 04 E6 27 27 2B
					39 00 00 40 00 00 04 E7 1D 22 23
					39 00 00 40 00 00 04 E8 1A 1A 19
					39 00 00 40 00 00 04 E9 10 0E 10
					39 00 00 40 00 00 04 EA 0E 0C 0D
					39 00 00 40 00 00 04 EB 05 05 05
					39 00 00 40 00 00 04 FF 5A A5 5C
					39 00 00 40 00 00 04 80 03 05 04
					39 00 00 40 00 00 04 81 03 03 03
					39 00 00 40 00 00 04 82 02 02 02
					39 00 00 40 00 00 04 83 04 05 04
					39 00 00 40 00 00 04 84 02 03 03
					39 00 00 40 00 00 04 85 01 02 02
					39 00 00 40 00 00 04 86 12 14 13
					39 00 00 40 00 00 04 87 0D 0E 0C
					39 00 00 40 00 00 04 88 0A 08 07
					39 00 00 40 00 00 04 89 04 04 03
					39 00 00 40 00 00 04 8A 1C 1C 1B
					39 00 00 40 00 00 04 8B 16 16 14
					39 00 00 40 00 00 04 8C 10 0F 0F
					39 00 00 40 00 00 04 8D 0A 0C 0A
					39 00 00 40 00 00 04 8E 05 07 06
					39 00 00 40 00 00 04 8F 20 21 22
					39 00 00 40 00 00 04 90 1C 1E 1D
					39 00 00 40 00 00 04 91 13 14 14
					39 00 00 40 00 00 04 92 0E 0F 0D
					39 00 00 40 00 00 04 93 05 07 06
					39 00 00 40 00 00 04 94 01 03 01
					39 00 00 40 00 00 04 95 2E 2E 33
					39 00 00 40 00 00 04 96 1D 1F 26
					39 00 00 40 00 00 04 97 17 1A 1C
					39 00 00 40 00 00 04 98 12 15 16
					39 00 00 40 00 00 04 99 0F 11 13
					39 00 00 40 00 00 04 9A 06 08 07
					39 00 00 40 00 00 04 9B 05 06 05
					39 00 00 40 00 00 04 9C 34 36 33
					39 00 00 40 00 00 04 9D 29 2C 29
					39 00 00 40 00 00 04 9E 29 2B 24
					39 00 00 40 00 00 04 9F 22 21 22
					39 00 00 40 00 00 04 A0 19 1F 18
					39 00 00 40 00 00 04 A1 0D 11 0C
					39 00 00 40 00 00 04 A2 0A 0D 0C
					39 00 00 40 00 00 04 A3 00 00 00
					39 00 00 40 00 00 04 A4 02 02 02
					39 00 00 40 00 00 04 A5 01 01 02
					39 00 00 40 00 00 04 A6 01 02 01
					39 00 00 40 00 00 04 A7 07 08 09
					39 00 00 40 00 00 04 A8 03 03 04
					39 00 00 40 00 00 04 A9 02 02 03
					39 00 00 40 00 00 04 AA 10 10 11
					39 00 00 40 00 00 04 AB 0E 0F 10
					39 00 00 40 00 00 04 AC 0A 0B 0C
					39 00 00 40 00 00 04 AD 04 04 04
					39 00 00 40 00 00 04 AE 18 19 1A
					39 00 00 40 00 00 04 AF 16 15 15
					39 00 00 40 00 00 04 B0 12 11 10
					39 00 00 40 00 00 04 B1 0C 0D 0D
					39 00 00 40 00 00 04 B2 05 05 05
					39 00 00 40 00 00 04 B3 21 20 22
					39 00 00 40 00 00 04 B4 18 17 16
					39 00 00 40 00 00 04 B5 0F 10 10
					39 00 00 40 00 00 04 B6 0C 0B 0D
					39 00 00 40 00 00 04 B7 07 06 07
					39 00 00 40 00 00 04 B8 01 01 01
					39 00 00 40 00 00 04 B9 32 30 36
					39 00 00 40 00 00 04 BA 1A 1B 1B
					39 00 00 40 00 00 04 BB 18 1A 18
					39 00 00 40 00 00 04 BC 13 14 13
					39 00 00 40 00 00 04 BD 0E 10 0C
					39 00 00 40 00 00 04 BE 06 08 05
					39 00 00 40 00 00 04 BF 05 05 04
					39 00 00 40 00 00 04 C0 30 2C 32
					39 00 00 40 00 00 04 C1 25 2A 26
					39 00 00 40 00 00 04 C2 1D 2C 22
					39 00 00 40 00 00 04 C3 1A 1E 1C
					39 00 00 40 00 00 04 C4 16 1C 12
					39 00 00 40 00 00 04 C5 0C 10 0A
					39 00 00 40 00 00 04 C6 0B 0C 08
					39 00 00 40 00 00 04 C7 00 00 00
					39 00 00 40 00 00 04 C8 05 06 03
					39 00 00 40 00 00 04 C9 03 05 02
					39 00 00 40 00 00 04 CA 03 05 02
					39 00 00 40 00 00 04 CB 03 05 02
					39 00 00 40 00 00 04 CC 02 03 02
					39 00 00 40 00 00 04 CD 00 00 00
					39 00 00 40 00 00 04 CE 00 00 00
					39 00 00 40 00 00 04 CF 00 00 00
					39 00 00 00 00 00 04 FF 5A A5 00
					39 00 00 00 78 00 01 11 // Sleep out
					39 00 00 00 00 00 01 29 // Display out
				];
				oplus,dsi-aod-off-command = [
					39 00 00 40 00 00 04 FF 5A A5 00
					39 00 00 40 00 00 02 38 00
					39 00 00 00 00 00 05 51 00 00 00 00
				];
				oplus,dsi-ultra-low-power-aod-on-command = [
				];
				oplus,dsi-ultra-low-power-aod-off-command = [
				];
				oplus,dsi-hbm-on-command = [
					39 00 00 00 00 00 03 51 0E 7A
				];
				oplus,dsi-hbm-off-command = [
					39 00 00 00 00 00 03 51 0D BB
				];
				oplus,dsi-timing-switch-command-state = "dsi_hs_mode";
				oplus,dsi-timing-switch-1pulse-command-state = "dsi_hs_mode";
				oplus,dsi-on-command-state = "dsi_lp_mode";
				oplus,dsi-aod-off-command-state = "dsi_ls_mode";
				oplus,dsi-ultra-low-power-aod-on-command-state = "dsi_ls_mode";
				oplus,dsi-ultra-low-power-aod-off-command-state = "dsi_ls_mode";
				oplus,dsi-hbm-on-command-state = "dsi_hs_mode";
				oplus,dsi-hbm-off-command-state = "dsi_hs_mode";
				oplus,dsc-params-entries = <&dsc_params>;
				oplus,spr-params-entries = <&spr_params>;
				oplus,dyn-fps {
					switch_en = <1>;
					vact_timing_fps = <90>;
					apollo_limit_superior_us = <7880>;
					apollo_limit_inferior_us = <10000>;
					apollo_transfer_time_us = <8800>;
				};
				oplus,display-mode {
					display-mode@0 {
						hdisplay = <1256>;
						vdisplay = <2760>;
						fhd-hfp = <9>;
						fhd-hsa = <2>;
						fhd-hbp = <21>;
						fhd-vfp = <52>;
						fhd-vsa = <14>;
						fhd-vbp = <22>;
						hskew = <STANDARD_ADFR>;
					};
					display-mode@1 {
						hdisplay = <1080>;
						vdisplay = <2374>;
						fhd-hfp = <9>;
						fhd-hsa = <2>;
						fhd-hbp = <21>;
						fhd-vfp = <66>;
						fhd-vsa = <24>;
						fhd-vbp = <36>;
						hskew = <STANDARD_ADFR>;
					};
				};
			};
			timing@sa_fhd_60 {
				cell-index = <2>;
				mtk,skip_vblank = <1>;
				mtk,real_te_duration = <16667>;
				oplus,dsi-panel-framerate = <60>;
				oplus,dsi-panel-pllclk = <414>;
				/* OPLUS_FEATURE_DISPLAY_ONSCREENFINGERPRINT */
				oplus,ofp_need_keep_apart_backlight;
				oplus,ofp-hbm-on-delay = <0>;
				oplus,ofp-pre-hbm-off-delay = <2>;
				oplus,ofp-hbm-off-delay = <0>;
				oplus,ofp-need-to-sync-data-in-aod-unlocking;
				oplus,ofp-aod-off-insert-black = <1>;
				oplus,ofp-aod-off-black-frame-total-time = <42>;
				#include "panel-ac287-p-7-a0020-dsi-cmd-common.dtsi"
				oplus,dsi-timing-switch-command = [
					39 00 00 40 00 00 04 FF 5A A5 00
					15 00 00 40 00 00 02 60 04
					15 00 00 00 00 00 02 7D 01
				];
				oplus,dsi-on-command = [
					39 00 00 40 00 00 04 FF 5A A5 08 // 1~2: Sleepoutdon'treload
					15 00 00 40 00 00 02 C8 62
					39 00 00 40 00 00 04 FF 5A A5 21 // 3~4:  Flashreloadenable
					15 00 00 40 00 00 02 A4 38
					39 00 00 40 00 00 04 FF 5A A5 23
					15 00 00 40 00 00 02 85 15
					39 00 00 40 00 00 04 FF 5A A5 07
					15 00 00 40 00 00 02 8A 01
					39 00 00 40 00 00 03 8B 21 E0
					39 00 00 40 00 00 64 80 00 00 00 00 00 12 00 00 AB 30 80 0A C8 04 E8 00 14 02 74 02 74 02 00 02 56 00 20 01 B9 00 08 00 0D 05 7A 04 64 18 00 11 00 07 10 20 00 06 0F 0F 33 0E 1C 2A 38 46 54 62 69 70 77 79 7B 7D 7E 02 02 22 00 2A 40 2A BE 3A FC 3A FA 3A F8 3B 38 3B 78 3B B6 4B B6 4B F4 4B F4 6C 34 84 74 00 00 00 00 00 00
					39 00 00 40 00 00 64 81 00 00 00 00 00 12 00 00 A0 21 00 0A C8 04 E8 00 14 02 74 02 74 01 55 01 D6 00 0A 01 10 00 34 00 0D 05 7A 18 C0 08 00 0C 10 07 10 20 00 06 0F 0F 33 0E 1C 2A 38 46 54 62 69 70 77 79 7B 7D 7E 00 82 11 40 19 C0 22 3E 32 7C 3A BA 3A F8 3B 38 3B 38 3B 76 4B 76 4B 74 4B 74 5B B4 73 F4 01 00 00 00 00 00
					39 00 00 40 00 00 04 FF 5A A5 07
					15 00 00 40 00 00 02 91 00
					39 00 00 40 00 00 04 FF 5A A5 14
					15 00 00 40 00 00 02 82 01       //SPR IN AP ON
					39 00 00 40 00 00 04 FF 5A A5 14
					15 00 00 40 00 00 02 80 00      //DDIC SPR OFF
					// DDIC corner off
					39 00 00 40 00 00 04 FF 5A A5 17
					15 00 00 40 00 00 02 A0 0C
					39 00 00 40 00 00 04 FF 5A A5 13
					15 00 00 40 00 00 02 F9 30
					// 1 bit esd
					39 00 00 40 00 00 04 FF 5A A5 06
					15 00 00 40 00 00 02 C6 01
					39 00 00 40 00 00 04 FF 5A A5 08
					15 00 00 40 00 00 02 D2 05
					15 00 00 40 00 00 02 D3 01
					39 00 00 40 00 00 09 ED FF FF FF FF FF FF 45 FF
					39 00 00 40 00 00 09 EE FF FD FF FD F9 FA BE 76
					39 00 00 40 00 00 04 FF 5A A5 24
					39 00 00 40 00 00 31 D2 10 ED 04 83 03 0B 02 30 01 7A 00 FC 00 A9 00 01 00 00 00 00 00 00 00 00 00 00 00 00 00 00 00 00 00 00 00 00 00 00 00 00 00 00 00 00 00 00 00 00
					39 00 00 40 00 00 31 D3 04 84 03 0B 02 30 01 7A 00 FC 00 A9 00 01 00 00 00 00 00 00 00 00 00 00 00 00 00 00 00 00 00 00 00 00 00 00 00 00 00 00 00 00 00 00 00 00 00 00
					39 00 00 40 00 00 04 FF 5A A5 00
					15 00 00 40 00 00 02 5E 01
					15 00 00 40 00 00 02 60 00
					15 00 00 40 00 00 02 61 02
					15 00 00 40 00 00 02 6D 01
					15 00 00 40 00 00 02 35 00 //TE on
					15 00 00 40 00 00 02 53 20 // BC On
					// pull dowm pmic
					39 00 00 40 00 00 04 FF 5A A5 1C
					39 00 00 40 00 00 16 E1 10 80 9A 65 59 54 69 95 56 6A 55 99 9A 55 55 25 58 55 66 A2 00
					39 00 00 40 00 00 04 FF 5A A5 05
					15 00 00 40 00 00 02 83 01
					// LGOCB change to 30
					39 00 00 40 00 00 04 FF 5A A5 53
					39 00 00 40 00 00 1F A2 10 10 10 10 10 10 10 10 30 30 10 10 10 10 10 10 10 10 30 30 10 10 10 10 10 10 10 10 30 30
					39 00 00 00 00 00 04 FF 5A A5 00
					// crc reset
					39 00 00 40 00 00 04 FF 5A A5 08
					15 00 00 40 00 00 02 E0 22
					// timing switch
					39 00 00 40 00 00 04 FF 5A A5 22
					39 00 00 40 00 00 08 D8 00 FE 11 10 3A 18 18
					39 00 00 40 00 00 08 D9 01 03 11 10 50 18 18
					39 00 00 40 00 00 08 DA 01 04 11 10 50 19 19
					39 00 00 40 00 00 0A DC 84 94 BB 00 20 C4 A1 CC 10
					15 00 00 40 00 00 02 DD 01
					15 00 00 40 00 00 02 DE F1
					15 00 00 40 00 00 02 DF 80
					39 00 00 40 00 00 07 E0 02 00 5F 21 00 28
					39 00 00 40 00 00 04 FF 5A A5 00
					15 00 00 40 00 00 02 60 04
					15 00 00 00 00 00 02 7D 01
					// odc refresh
					39 00 00 40 00 00 04 FF 5A A5 49
					39 00 00 40 00 00 0C 80 00 08 0C 1C 3C 7C 8C CC 0C 00 01
					39 00 00 40 00 00 11 81 01 00 BD 00 18 01 85 01 42 02 A6 03 DD 06 FF 07
					39 00 00 40 00 00 13 82 01 00 BD 00 18 01 85 01 42 02 A6 03 DD 06 FF 07 00 00
					15 00 00 40 00 00 02 83 07
					15 00 00 40 00 00 02 84 0A
					39 00 00 40 00 00 04 85 08 0C 00
					39 00 00 40 00 00 04 86 40 80 00
					39 00 00 40 00 00 04 A0 40 40 40
					39 00 00 40 00 00 04 A1 40 40 40
					39 00 00 40 00 00 04 A2 40 40 40
					15 00 00 40 00 00 02 A6 3F
					15 00 00 40 00 00 02 A7 07
					15 00 00 40 00 00 02 AD 01
					15 00 00 40 00 00 02 AE 00
					15 00 00 40 00 00 02 AF 00
					15 00 00 40 00 00 02 D9 02
					15 00 00 40 00 00 02 DA F7
					15 00 00 40 00 00 02 DB 9C
					15 00 00 40 00 00 02 DC 03
					15 00 00 40 00 00 02 DF 06
					15 00 00 40 00 00 02 E0 01
					39 00 00 40 00 00 04 FF 5A A5 5A
					39 00 00 40 00 00 04 80 0D 0E 0D
					39 00 00 40 00 00 04 81 11 12 11
					39 00 00 40 00 00 04 82 07 08 07
					39 00 00 40 00 00 04 83 19 1C 1A
					39 00 00 40 00 00 04 84 14 15 13
					39 00 00 40 00 00 04 85 07 0A 08
					39 00 00 40 00 00 04 86 20 34 1A
					39 00 00 40 00 00 04 87 18 36 15
					39 00 00 40 00 00 04 88 1E 34 E0
					39 00 00 40 00 00 04 89 15 38 E0
					39 00 00 40 00 00 04 8A 32 32 32
					39 00 00 40 00 00 04 8B 2D 2D 28
					39 00 00 40 00 00 04 8C 27 1D 26
					39 00 00 40 00 00 04 8D 18 18 1D
					39 00 00 40 00 00 04 8E 0D 08 0D
					39 00 00 40 00 00 04 8F 20 24 24
					39 00 00 40 00 00 04 90 0D 10 10
					39 00 00 40 00 00 04 91 0F 10 10
					39 00 00 40 00 00 04 92 12 13 10
					39 00 00 40 00 00 04 93 05 05 06
					39 00 00 40 00 00 04 94 03 03 03
					39 00 00 40 00 00 04 95 33 37 3B
					39 00 00 40 00 00 04 96 32 33 2D
					39 00 00 40 00 00 04 97 26 27 22
					39 00 00 40 00 00 04 98 1A 1C 18
					39 00 00 40 00 00 04 99 12 13 10
					39 00 00 40 00 00 04 9A 06 07 06
					39 00 00 40 00 00 04 9B 04 04 03
					39 00 00 40 00 00 04 9C 36 3A 38
					39 00 00 40 00 00 04 9D 36 38 2D
					39 00 00 40 00 00 04 9E 24 26 16
					39 00 00 40 00 00 04 9F 1E 20 1C
					39 00 00 40 00 00 04 A0 15 17 14
					39 00 00 40 00 00 04 A1 0A 0B 0B
					39 00 00 40 00 00 04 A2 08 08 09
					39 00 00 40 00 00 04 A3 04 04 04
					39 00 00 40 00 00 04 A4 0B 0C 0B
					39 00 00 40 00 00 04 A5 0D 0E 0D
					39 00 00 40 00 00 04 A6 06 08 06
					39 00 00 40 00 00 04 A7 11 13 11
					39 00 00 40 00 00 04 A8 0F 10 10
					39 00 00 40 00 00 04 A9 05 06 05
					39 00 00 40 00 00 04 AA 19 1C 1B
					39 00 00 40 00 00 04 AB 14 17 15
					39 00 00 40 00 00 04 AC 0B 0F 0A
					39 00 00 40 00 00 04 AD 06 08 06
					39 00 00 40 00 00 04 AE 1B 1E 1B
					39 00 00 40 00 00 04 AF 18 1B 17
					39 00 00 40 00 00 04 B0 10 12 10
					39 00 00 40 00 00 04 B1 0D 0E 0A
					39 00 00 40 00 00 04 B2 03 05 04
					39 00 00 40 00 00 04 B3 18 1C 1A
					39 00 00 40 00 00 04 B4 16 18 16
					39 00 00 40 00 00 04 B5 12 14 10
					39 00 00 40 00 00 04 B6 07 0A 09
					39 00 00 40 00 00 04 B7 05 08 07
					39 00 00 40 00 00 04 B8 02 03 02
					39 00 00 40 00 00 04 B9 20 24 20
					39 00 00 40 00 00 04 BA 1C 1F 1D
					39 00 00 40 00 00 04 BB 16 1A 15
					39 00 00 40 00 00 04 BC 12 16 15
					39 00 00 40 00 00 04 BD 0B 0D 10
					39 00 00 40 00 00 04 BE 06 08 08
					39 00 00 40 00 00 04 BF 04 06 05
					39 00 00 40 00 00 04 C0 24 26 32
					39 00 00 40 00 00 04 C1 1D 17 23
					39 00 00 40 00 00 04 C2 1B 16 22
					39 00 00 40 00 00 04 C3 1A 17 20
					39 00 00 40 00 00 04 C4 17 16 1C
					39 00 00 40 00 00 04 C5 10 0F 0E
					39 00 00 40 00 00 04 C6 0F 0E 0B
					39 00 00 40 00 00 04 C7 0C 0D 0B
					39 00 00 40 00 00 04 C8 05 07 04
					39 00 00 40 00 00 04 C9 09 0C 09
					39 00 00 40 00 00 04 CA 04 06 05
					39 00 00 40 00 00 04 CB 14 1D 12
					39 00 00 40 00 00 04 CC 10 16 0D
					39 00 00 40 00 00 04 CD 03 05 02
					39 00 00 40 00 00 04 CE 0F 12 10
					39 00 00 40 00 00 04 CF 0E 10 0E
					39 00 00 40 00 00 04 D0 07 0A 08
					39 00 00 40 00 00 04 D1 02 04 01
					39 00 00 40 00 00 04 D2 17 1A 19
					39 00 00 40 00 00 04 D3 14 16 13
					39 00 00 40 00 00 04 D4 09 0C 0A
					39 00 00 40 00 00 04 D5 04 06 08
					39 00 00 40 00 00 04 D6 03 04 05
					39 00 00 40 00 00 04 D7 1D 1F 1C
					39 00 00 40 00 00 04 D8 0C 12 0D
					39 00 00 40 00 00 04 D9 09 0D 0B
					39 00 00 40 00 00 04 DA 06 0A 0A
					39 00 00 40 00 00 04 DB 05 05 07
					39 00 00 40 00 00 04 DC 01 03 01
					39 00 00 40 00 00 04 DD 22 23 20
					39 00 00 40 00 00 04 DE 15 18 1A
					39 00 00 40 00 00 04 DF 13 15 16
					39 00 00 40 00 00 04 E0 0F 13 14
					39 00 00 40 00 00 04 E1 0D 0F 10
					39 00 00 40 00 00 04 E2 07 08 08
					39 00 00 40 00 00 04 E3 06 07 06
					39 00 00 40 00 00 04 E4 2F 2D 35
					39 00 00 40 00 00 04 E5 20 20 28
					39 00 00 40 00 00 04 E6 1E 24 29
					39 00 00 40 00 00 04 E7 1B 1A 23
					39 00 00 40 00 00 04 E8 1B 1F 1E
					39 00 00 40 00 00 04 E9 0E 13 11
					39 00 00 40 00 00 04 EA 0B 10 0F
					39 00 00 40 00 00 04 EB 09 0A 07
					39 00 00 40 00 00 04 FF 5A A5 5B
					39 00 00 40 00 00 04 80 05 07 04
					39 00 00 40 00 00 04 81 05 08 07
					39 00 00 40 00 00 04 82 04 04 05
					39 00 00 40 00 00 04 83 11 16 0F
					39 00 00 40 00 00 04 84 0F 11 0D
					39 00 00 40 00 00 04 85 03 05 02
					39 00 00 40 00 00 04 86 08 0B 07
					39 00 00 40 00 00 04 87 04 05 06
					39 00 00 40 00 00 04 88 03 04 03
					39 00 00 40 00 00 04 89 02 02 01
					39 00 00 40 00 00 04 8A 11 14 13
					39 00 00 40 00 00 04 8B 0B 0D 0E
					39 00 00 40 00 00 04 8C 06 07 09
					39 00 00 40 00 00 04 8D 05 06 08
					39 00 00 40 00 00 04 8E 04 04 05
					39 00 00 40 00 00 04 8F 1A 1F 1D
					39 00 00 40 00 00 04 90 14 16 15
					39 00 00 40 00 00 04 91 0E 11 0F
					39 00 00 40 00 00 04 92 07 0A 09
					39 00 00 40 00 00 04 93 06 05 07
					39 00 00 40 00 00 04 94 02 03 01
					39 00 00 40 00 00 04 95 2E 32 31
					39 00 00 40 00 00 04 96 28 2C 2A
					39 00 00 40 00 00 04 97 18 1D 19
					39 00 00 40 00 00 04 98 13 14 13
					39 00 00 40 00 00 04 99 0F 0E 0F
					39 00 00 40 00 00 04 9A 07 08 08
					39 00 00 40 00 00 04 9B 06 07 06
					39 00 00 40 00 00 04 9C 2D 2E 3F
					39 00 00 40 00 00 04 9D 21 20 29
					39 00 00 40 00 00 04 9E 21 20 29
					39 00 00 40 00 00 04 9F 21 20 25
					39 00 00 40 00 00 04 A0 1B 17 1C
					39 00 00 40 00 00 04 A1 10 0F 13
					39 00 00 40 00 00 04 A2 0E 0D 0F
					39 00 00 40 00 00 04 A3 08 08 05
					39 00 00 40 00 00 04 A4 05 08 04
					39 00 00 40 00 00 04 A5 05 07 04
					39 00 00 40 00 00 04 A6 04 05 04
					39 00 00 40 00 00 04 A7 05 07 05
					39 00 00 40 00 00 04 A8 04 06 03
					39 00 00 40 00 00 04 A9 02 03 02
					39 00 00 40 00 00 04 AA 0F 11 10
					39 00 00 40 00 00 04 AB 0A 0B 08
					39 00 00 40 00 00 04 AC 06 07 05
					39 00 00 40 00 00 04 AD 03 02 02
					39 00 00 40 00 00 04 AE 11 14 12
					39 00 00 40 00 00 04 AF 0C 0F 0E
					39 00 00 40 00 00 04 B0 0B 0A 0A
					39 00 00 40 00 00 04 B1 05 07 08
					39 00 00 40 00 00 04 B2 04 04 05
					39 00 00 40 00 00 04 B3 16 15 14
					39 00 00 40 00 00 04 B4 0F 10 10
					39 00 00 40 00 00 04 B5 0D 0C 0B
					39 00 00 40 00 00 04 B6 09 08 07
					39 00 00 40 00 00 04 B7 05 05 06
					39 00 00 40 00 00 04 B8 01 01 01
					39 00 00 40 00 00 04 B9 1D 1C 21
					39 00 00 40 00 00 04 BA 16 16 1C
					39 00 00 40 00 00 04 BB 14 14 19
					39 00 00 40 00 00 04 BC 12 13 15
					39 00 00 40 00 00 04 BD 0D 0D 10
					39 00 00 40 00 00 04 BE 06 07 08
					39 00 00 40 00 00 04 BF 05 06 06
					39 00 00 40 00 00 04 C0 27 2E 3E
					39 00 00 40 00 00 04 C1 22 1C 2D
					39 00 00 40 00 00 04 C2 1E 20 26
					39 00 00 40 00 00 04 C3 1E 24 25
					39 00 00 40 00 00 04 C4 17 14 1A
					39 00 00 40 00 00 04 C5 0E 0F 0E
					39 00 00 40 00 00 04 C6 0C 0C 0D
					39 00 00 40 00 00 04 C7 04 05 05
					39 00 00 40 00 00 04 C8 05 07 04
					39 00 00 40 00 00 04 C9 04 06 04
					39 00 00 40 00 00 04 CA 03 04 03
					39 00 00 40 00 00 04 CB 07 07 08
					39 00 00 40 00 00 04 CC 02 03 03
					39 00 00 40 00 00 04 CD 00 01 01
					39 00 00 40 00 00 04 CE 06 06 08
					39 00 00 40 00 00 04 CF 03 04 03
					39 00 00 40 00 00 04 D0 02 03 02
					39 00 00 40 00 00 04 D1 01 03 01
					39 00 00 40 00 00 04 D2 11 11 14
					39 00 00 40 00 00 04 D3 0B 0C 0C
					39 00 00 40 00 00 04 D4 09 0A 0B
					39 00 00 40 00 00 04 D5 07 08 09
					39 00 00 40 00 00 04 D6 05 04 05
					39 00 00 40 00 00 04 D7 15 16 18
					39 00 00 40 00 00 04 D8 10 12 16
					39 00 00 40 00 00 04 D9 0D 0C 0F
					39 00 00 40 00 00 04 DA 09 0B 0B
					39 00 00 40 00 00 04 DB 07 06 07
					39 00 00 40 00 00 04 DC 01 01 01
					39 00 00 40 00 00 04 DD 23 1F 2C
					39 00 00 40 00 00 04 DE 1A 1C 1F
					39 00 00 40 00 00 04 DF 18 19 1B
					39 00 00 40 00 00 04 E0 13 16 16
					39 00 00 40 00 00 04 E1 0F 0F 10
					39 00 00 40 00 00 04 E2 07 08 07
					39 00 00 40 00 00 04 E3 05 06 06
					39 00 00 40 00 00 04 E4 37 36 3A
					39 00 00 40 00 00 04 E5 28 28 2D
					39 00 00 40 00 00 04 E6 27 27 2B
					39 00 00 40 00 00 04 E7 1D 22 23
					39 00 00 40 00 00 04 E8 1A 1A 19
					39 00 00 40 00 00 04 E9 10 0E 10
					39 00 00 40 00 00 04 EA 0E 0C 0D
					39 00 00 40 00 00 04 EB 05 05 05
					39 00 00 40 00 00 04 FF 5A A5 5C
					39 00 00 40 00 00 04 80 03 05 04
					39 00 00 40 00 00 04 81 03 03 03
					39 00 00 40 00 00 04 82 02 02 02
					39 00 00 40 00 00 04 83 04 05 04
					39 00 00 40 00 00 04 84 02 03 03
					39 00 00 40 00 00 04 85 01 02 02
					39 00 00 40 00 00 04 86 12 14 13
					39 00 00 40 00 00 04 87 0D 0E 0C
					39 00 00 40 00 00 04 88 0A 08 07
					39 00 00 40 00 00 04 89 04 04 03
					39 00 00 40 00 00 04 8A 1C 1C 1B
					39 00 00 40 00 00 04 8B 16 16 14
					39 00 00 40 00 00 04 8C 10 0F 0F
					39 00 00 40 00 00 04 8D 0A 0C 0A
					39 00 00 40 00 00 04 8E 05 07 06
					39 00 00 40 00 00 04 8F 20 21 22
					39 00 00 40 00 00 04 90 1C 1E 1D
					39 00 00 40 00 00 04 91 13 14 14
					39 00 00 40 00 00 04 92 0E 0F 0D
					39 00 00 40 00 00 04 93 05 07 06
					39 00 00 40 00 00 04 94 01 03 01
					39 00 00 40 00 00 04 95 2E 2E 33
					39 00 00 40 00 00 04 96 1D 1F 26
					39 00 00 40 00 00 04 97 17 1A 1C
					39 00 00 40 00 00 04 98 12 15 16
					39 00 00 40 00 00 04 99 0F 11 13
					39 00 00 40 00 00 04 9A 06 08 07
					39 00 00 40 00 00 04 9B 05 06 05
					39 00 00 40 00 00 04 9C 34 36 33
					39 00 00 40 00 00 04 9D 29 2C 29
					39 00 00 40 00 00 04 9E 29 2B 24
					39 00 00 40 00 00 04 9F 22 21 22
					39 00 00 40 00 00 04 A0 19 1F 18
					39 00 00 40 00 00 04 A1 0D 11 0C
					39 00 00 40 00 00 04 A2 0A 0D 0C
					39 00 00 40 00 00 04 A3 00 00 00
					39 00 00 40 00 00 04 A4 02 02 02
					39 00 00 40 00 00 04 A5 01 01 02
					39 00 00 40 00 00 04 A6 01 02 01
					39 00 00 40 00 00 04 A7 07 08 09
					39 00 00 40 00 00 04 A8 03 03 04
					39 00 00 40 00 00 04 A9 02 02 03
					39 00 00 40 00 00 04 AA 10 10 11
					39 00 00 40 00 00 04 AB 0E 0F 10
					39 00 00 40 00 00 04 AC 0A 0B 0C
					39 00 00 40 00 00 04 AD 04 04 04
					39 00 00 40 00 00 04 AE 18 19 1A
					39 00 00 40 00 00 04 AF 16 15 15
					39 00 00 40 00 00 04 B0 12 11 10
					39 00 00 40 00 00 04 B1 0C 0D 0D
					39 00 00 40 00 00 04 B2 05 05 05
					39 00 00 40 00 00 04 B3 21 20 22
					39 00 00 40 00 00 04 B4 18 17 16
					39 00 00 40 00 00 04 B5 0F 10 10
					39 00 00 40 00 00 04 B6 0C 0B 0D
					39 00 00 40 00 00 04 B7 07 06 07
					39 00 00 40 00 00 04 B8 01 01 01
					39 00 00 40 00 00 04 B9 32 30 36
					39 00 00 40 00 00 04 BA 1A 1B 1B
					39 00 00 40 00 00 04 BB 18 1A 18
					39 00 00 40 00 00 04 BC 13 14 13
					39 00 00 40 00 00 04 BD 0E 10 0C
					39 00 00 40 00 00 04 BE 06 08 05
					39 00 00 40 00 00 04 BF 05 05 04
					39 00 00 40 00 00 04 C0 30 2C 32
					39 00 00 40 00 00 04 C1 25 2A 26
					39 00 00 40 00 00 04 C2 1D 2C 22
					39 00 00 40 00 00 04 C3 1A 1E 1C
					39 00 00 40 00 00 04 C4 16 1C 12
					39 00 00 40 00 00 04 C5 0C 10 0A
					39 00 00 40 00 00 04 C6 0B 0C 08
					39 00 00 40 00 00 04 C7 00 00 00
					39 00 00 40 00 00 04 C8 05 06 03
					39 00 00 40 00 00 04 C9 03 05 02
					39 00 00 40 00 00 04 CA 03 05 02
					39 00 00 40 00 00 04 CB 03 05 02
					39 00 00 40 00 00 04 CC 02 03 02
					39 00 00 40 00 00 04 CD 00 00 00
					39 00 00 40 00 00 04 CE 00 00 00
					39 00 00 40 00 00 04 CF 00 00 00
					39 00 00 00 00 00 04 FF 5A A5 00
					39 00 00 00 78 00 01 11 // Sleep out
					39 00 00 00 00 00 01 29 // Display out
				];
				oplus,dsi-aod-off-command = [
					39 00 00 40 00 00 04 FF 5A A5 00
					39 00 00 40 00 00 02 38 00
					39 00 00 00 00 00 05 51 00 00 00 00
				];
				oplus,dsi-ultra-low-power-aod-on-command = [
				];
				oplus,dsi-ultra-low-power-aod-off-command = [
				];
				oplus,dsi-hbm-on-command = [
					39 00 00 00 00 00 03 51 0E 7A
				];
				oplus,dsi-hbm-off-command = [
					39 00 00 00 00 00 03 51 0D BB
				];
				oplus,dsi-timing-switch-command-state = "dsi_hs_mode";
				oplus,dsi-on-command-state = "dsi_lp_mode";
				oplus,dsi-aod-off-command-state = "dsi_ls_mode";
				oplus,dsi-ultra-low-power-aod-on-command-state = "dsi_ls_mode";
				oplus,dsi-ultra-low-power-aod-off-command-state = "dsi_ls_mode";
				oplus,dsi-hbm-on-command-state = "dsi_hs_mode";
				oplus,dsi-hbm-off-command-state = "dsi_hs_mode";
				oplus,dsc-params-entries = <&dsc_params>;
				oplus,spr-params-entries = <&spr_params>;
				oplus,dyn-fps {
					switch_en = <1>;
					vact_timing_fps = <60>;
					apollo_limit_superior_us = <11540>;
					apollo_limit_inferior_us = <15500>;
					apollo_transfer_time_us = <7800>;
				};
				oplus,display-mode {
					display-mode@0 {
						hdisplay = <1256>;
						vdisplay = <2760>;
						fhd-hfp = <9>;
						fhd-hsa = <2>;
						fhd-hbp = <21>;
						fhd-vfp = <52>;
						fhd-vsa = <14>;
						fhd-vbp = <22>;
						hskew = <STANDARD_MFR>;
					};
				display-mode@1 {
						hdisplay = <1080>;
						vdisplay = <2374>;
						fhd-hfp = <9>;
						fhd-hsa = <2>;
						fhd-hbp = <21>;
						fhd-vfp = <66>;
						fhd-vsa = <24>;
						fhd-vbp = <36>;
						hskew = <STANDARD_MFR>;
					};
				};
			};
		};
	};
};

&panel_ac287_p_7_a0020_dsi_cmd {
	oplus,dsi-display-panel@0 {
		res-switch = <2>;
		/* Hardware config */
		oplus,panel-supply-entries = <&dsi_panel_pwr_supply>;
		oplus,panel-power-on-sequence = "1", "vddi", "5", "vddr", "1", "1p2", "5", "vci", "1";
		oplus,panel-power-off-sequence = "2", "vci", "5", "1p2", "1", "vddr", "5", "vddi", "1";
		reset-gpios = <&pio 89 0>;
		oplus,panel-reset-sequence = <2 10>, <1 1>, <0 1>, <1 20>;
		oplus,pmic_reset_enable;
		pmic-reset-gpios = <&pio 79 0>;
		/* Panel config */
		oplus,dsi-serial-number-enabled=<1>;
		oplus,dsi-serial-number-switch-page;
		oplus,dsi-serial-number-index= <0>;
		oplus,dsi-serial-number-switch-page-command= <0xFF 0x5A 0xA5 0x1D>;
		oplus,dsi-serial-number-default-switch-page-command= <0xFF 0x5A 0xA5 0x00>;
		oplus,dsi-serial-number-reg= <0x80>;
		oplus,dsi-serial-number-read-count= <7>;
		oplus,dsi-serial-number-year-offset= <0>;
		/* btb-sn config */
		oplus,dsi-btb-sn-enabled;
		oplus,dsi-btb-sn-switch-page;
		oplus,dsi-btb-sn-reg= <0x82>;
		oplus,dsi-btb-sn-index= <0>;
		oplus,dsi-btb-sn-read-count= <32>;
		oplus,mode-switch-h2l-delay;
		oplus,keep_ulps = <1>;
		/* PWM config */
		oplus,pwm-turbo-support = <1>; /* 0 not support, 1 with switch, 2 Global high frequency pwm without switch */
		oplus,pwm-switch-backlight-threshold = <0>;
		oplus,pwm-onepulse-support = <0>;
		oplus,pwm-onepulse-enabled = <0>;
		oplus,pwm-turbo-wait-te = <1>;
		/* ADFR config */
		oplus-adfr-config = <0>;
		/* OFP config */
		oplus,ofp-fp-type = <0x1c0>;
		oplus,ofp-longrui-aod-config = <0x0E>;
		/* ext_params */
		oplus,panel-type = <2>;
		oplus,lane-swap-en = <0>;
		oplus,lane-swap = <
			MIPITX_PHY_LANE_0 MIPITX_PHY_LANE_1 MIPITX_PHY_LANE_3 MIPITX_PHY_LANE_2 MIPITX_PHY_LANE_CK MIPITX_PHY_LANE_0
			MIPITX_PHY_LANE_0 MIPITX_PHY_LANE_1 MIPITX_PHY_LANE_3 MIPITX_PHY_LANE_2 MIPITX_PHY_LANE_CK MIPITX_PHY_LANE_0
		>;
		oplus,lcm-color-mode = <MTK_DRM_COLOR_MODE_DISPLAY_P3>;
		oplus,output-mode = <MTK_PANEL_DSC_SINGLE_PORT>;
		oplus,panel-bpp = <10>;
		oplus,physical-width-um = <69331>;
		oplus,physical-height-um = <152352>;
		/* color */
		oplus,color-vivid-status;
		oplus,color-srgb-status;
		// oplus,color-softiris-status;
		// oplus,color-dual-panel-status;
		oplus,color-dual-brightness-status;
		oplus,color-oplus-calibrate-status;
		// oplus,color-samsung-status;
		oplus,color-loading-status;
		oplus,color-2nit-status;
		// oplus,color-nature-profession-status;
		/* ESD */
		oplus,cust-esd-check = <0>; // both check TE and reg
		oplus,esd-check-enable = <1>;
		oplus,esd_check_cmd = [
			0A
		];
		oplus,esd_check_count = [
			01
		];
		oplus,esd_check_value = [
			9C
		];
		oplus,esd_check_mask = [
			FF
		];
		/* MIPI error check config */
		/*
		 ** BIT(0): enable/disable check
		 ** BIT(1): enable/disable page switch
		 */
		oplus,mipi-err-check-config = <0x01>; // 0b0000'0111
		oplus,mipi-err-check-reg = [
			0E
		];
		oplus,mipi-err-check-value = [
			80
		];
		oplus,mipi-err-check-count = [
			01
		];
		/*  32-bit binary flag
		 ** Bit value identified how to match the return value of each register.
		 ** The value 0(default) means equal, and the value 1 means not equal.
		 */
		oplus,mipi-err-check-match-modes = <0x00000000>;
	};
};
